# RockChip_RK3588 register map
Vendor: RockChip Electronics Co., Ltd.; Series: RK3588; File version: 0.1
Registers are 32-bit, read-write, no defined reset value unless marked. A register's access mark holds for its fields unless they carry their own. Offsets are from the block's base; [hi:lo] are bit positions; {n}, {i} and the like mark numbered series.

## IOC_BUS
Base 0xFD5F8000
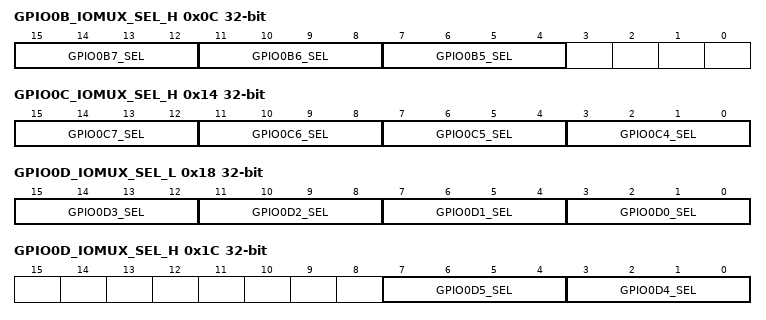
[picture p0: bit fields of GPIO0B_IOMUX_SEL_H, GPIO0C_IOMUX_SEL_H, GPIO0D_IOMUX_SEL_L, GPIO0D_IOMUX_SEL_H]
0x0C GPIO0B_IOMUX_SEL_H — GPIO0B IOMUX Select High bits
  [15:12] GPIO0B7_SEL
    8=SPI0_CS1_M0; 9=I2C2_SCL_M0; 11=CAN0_TX_M0; 12=PCIE30X1_1_PERSTN_M0
  [11:8] GPIO0B6_SEL
    9=I2C1_SDA_M0; 10=UART2_RX_M0; 12=PCIE30X1_1_WAKEN_M0
  [7:4] GPIO0B5_SEL
    9=I2C1_SCL_M0; 10=UART2_TX_M0; 12=PCIE30X1_1_CLKREQN_M0
0x10 GPIO0C_IOMUX_SEL_L — GPIO0C IOMUX Select Low bits
  [3:0] GPIO0C0_SEL
    8=SPI0_MOSI_M0; 9=I2C2_SDA_M0; 11=CAN0_RX_M0; 12=PCIE30X1_0_CLKREQN_M0
0x14 GPIO0C_IOMUX_SEL_H — GPIO0C IOMUX Select High bits
  [15:12] GPIO0C7_SEL
    8=SPI0_MISO_M0; 9=I2C6_SDA_M0; 10=UART1_RTSN_M2; 11=PWM6_M0; 12=PCIE30X4_WAKEN_M0
  [11:8] GPIO0C6_SEL
    8=SPI0_CLK_M0; 11=PWM5_M1; 12=PCIE30X4_CLKREQN_M0; 13=SATA_CP_POD
  [7:4] GPIO0C5_SEL
    9=I2C4_SCL_M2; 10=DP1_HPDIN_M1; 11=PWM4_M0; 12=PCIE30X1_0_PERSTN_M0
  [3:0] GPIO0C4_SEL
    9=I2C4_SDA_M2; 10=DP0_HPDIN_M1; 12=PCIE30X1_0_WAKEN_M0
0x18 GPIO0D_IOMUX_SEL_L — GPIO0D IOMUX Select Low bits
  [15:12] GPIO0D3_SEL
    8=SPI3_CLK_M2
  [11:8] GPIO0D2_SEL
    8=SPI3_MOSI_M2; 10=UART1_RX_M2; 11=HDMI_RX_SCL_M0; 12=PCIE30X2_WAKEN_M0; 13=HDMI_TX1_CEC_M1
  [7:4] GPIO0D1_SEL
    8=SPI0_CS0_M0; 10=UART1_TX_M2; 11=HDMI_RX_SDA_M0; 12=PCIE30X2_CLKREQN_M0; 13=HDMI_TX0_CEC_M1
  [3:0] GPIO0D0_SEL
    8=SPI3_MISO_M2; 9=I2C6_SCL_M0; 10=UART1_CTSN_M2; 11=PWM7_IR_M0; 12=PCIE30X4_PERSTN_M0
0x1C GPIO0D_IOMUX_SEL_H — GPIO0D IOMUX Select High bits
  [7:4] GPIO0D5_SEL
    8=SPI3_CS1_M2; 9=I2C1_SDA_M2; 10=CAN2_TX_M1; 11=HDMI_TX0_SCL_M1; 13=SATA_MP_SWITCH
  [3:0] GPIO0D4_SEL
    8=SPI3_CS0_M2; 9=I2C1_SCL_M2; 10=CAN2_RX_M1; 11=HDMI_TX0_SDA_M1; 12=PCIE30X2_PERSTN_M0; 13=SATA_CPDET
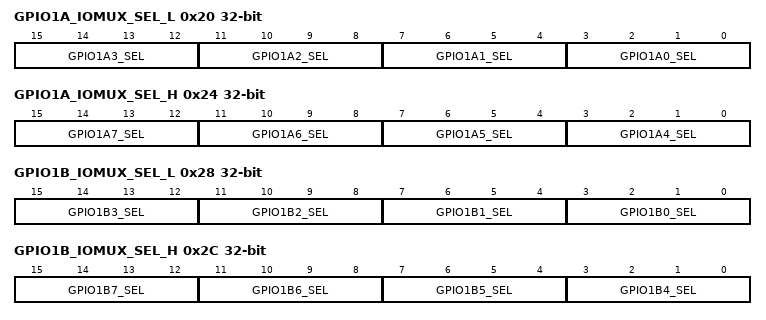
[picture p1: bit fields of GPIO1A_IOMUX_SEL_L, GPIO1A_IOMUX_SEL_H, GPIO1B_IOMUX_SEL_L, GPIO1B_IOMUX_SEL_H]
0x20 GPIO1A_IOMUX_SEL_L — GPIO1A IOMUX Select Low bits
  [15:12] GPIO1A3_SEL
    0=GPIO; 5=HDMI_TX1_SDA_M2; 8=SPI4_CS0_M2; 9=I2C4_SCL_M3; 10=UART6_CTSN_M1; 11=PWM1_M2
  [11:8] GPIO1A2_SEL
    0=GPIO; 1=VOP_POST_EMPTY; 8=SPI4_CLK_M2; 9=I2C4_SDA_M3; 10=UART6_RTSN_M1; 11=PWM0_M2
  [7:4] GPIO1A1_SEL
    0=GPIO; 4=PCIE30X1_1_WAKEN_M2; 5=DP1_HPDIN_M2; 6=SATA1_ACT_LED_M1; 8=SPI4_MOSI_M2; 9=I2C2_SCL_M4; 10=UART6_TX_M1
  [3:0] GPIO1A0_SEL
    0=GPIO; 4=PCIE30X1_1_CLKREQN_M2; 5=DP0_HPDIN_M2; 7=HDMI_DEBUG6; 8=SPI4_MISO_M2; 9=I2C2_SDA_M4; 10=UART6_RX_M1
0x24 GPIO1A_IOMUX_SEL_H — GPIO1A IOMUX Select High bits
  [15:12] GPIO1A7_SEL
    0=GPIO; 2=PDM1_SDI0_M1; 4=PCIE30X1_1_PERSTN_M2; 7=HDMI_DEBUG0; 8=SPI2_CS0_M0; 11=PWM3_IR_M3
  [11:8] GPIO1A6_SEL
    0=GPIO; 5=HDMI_TX1_HPD_M0; 8=SPI2_CLK_M0
  [7:4] GPIO1A5_SEL
    0=GPIO; 5=HDMI_TX0_HPD_M0; 8=SPI2_MOSI_M0
  [3:0] GPIO1A4_SEL
    0=GPIO; 5=HDMI_TX1_SCL_M2; 8=SPI2_MISO_M0
0x28 GPIO1B_IOMUX_SEL_L — GPIO1B IOMUX Select Low bits
  [15:12] GPIO1B3_SEL
    0=GPIO; 2=PDM1_CLK1_M1; 4=PCIE30X1_0_WAKEN_M2; 6=SATA0_ACT_LED_M1; 7=HDMI_DEBUG4; 8=SPI0_CLK_M2; 10=UART4_TX_M2
  [11:8] GPIO1B2_SEL
    0=GPIO; 2=PDM1_SDI3_M1; 4=PCIE30X4_PERSTN_M3; 7=HDMI_DEBUG3; 8=SPI0_MOSI_M2; 10=UART4_RX_M2
  [7:4] GPIO1B1_SEL
    0=GPIO; 2=PDM1_SDI2_M1; 4=PCIE30X4_WAKEN_M3; 7=HDMI_DEBUG2; 8=SPI0_MISO_M2
  [3:0] GPIO1B0_SEL
    0=GPIO; 2=PDM1_SDI1_M1; 4=PCIE30X4_CLKREQN_M3; 7=HDMI_DEBUG1; 8=SPI2_CS1_M0
0x2C GPIO1B_IOMUX_SEL_H — GPIO1B IOMUX Select High bits
  [15:12] GPIO1B7_SEL
    0=GPIO; 2=MIPI_CAMERA2_CLK_M0; 3=SPDIF1_TX_M0; 4=PCIE30X2_PERSTN_M3; 5=HDMI_RX_CEC_M2; 6=SATA2_ACT_LED_M1; 9=I2C5_SDA_M3; 10=UART1_RX_M1; 11=PWM13_M2
  [11:8] GPIO1B6_SEL
    0=GPIO; 2=MIPI_CAMERA1_CLK_M0; 3=SPDIF0_TX_M0; 4=PCIE30X2_WAKEN_M3; 5=HDMI_RX_HPDOUT_M2; 9=I2C5_SCL_M3; 10=UART1_TX_M1
  [7:4] GPIO1B5_SEL
    0=GPIO; 4=PCIE30X1_0_CLKREQN_M2; 8=SPI0_CS1_M2; 10=UART7_TX_M2
  [3:0] GPIO1B4_SEL
    0=GPIO; 2=PDM1_CLK0_M1; 4=PCIE30X1_0_PERSTN_M2; 7=HDMI_DEBUG5; 8=SPI0_CS0_M2; 10=UART7_RX_M2
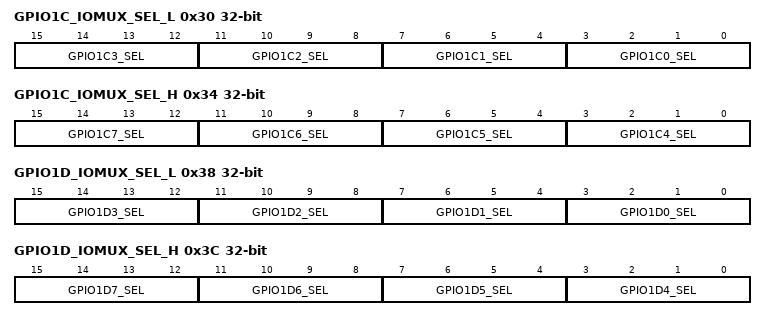
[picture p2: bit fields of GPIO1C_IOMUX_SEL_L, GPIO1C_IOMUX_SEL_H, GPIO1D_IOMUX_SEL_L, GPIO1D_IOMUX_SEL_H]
0x30 GPIO1C_IOMUX_SEL_L — GPIO1C IOMUX Select Low bits
  [15:12] GPIO1C3_SEL
    0=GPIO; 1=I2S0_SCLK; 8=SPI4_CS0_M0; 9=I2C6_SCL_M1; 10=UART3_CTSN; 11=PWM7_IR_M2
  [11:8] GPIO1C2_SEL
    0=GPIO; 1=I2S0_MCLK; 8=SPI4_CLK_M0; 9=I2C6_SDA_M1; 10=UART3_RTSN; 11=PWM3_IR_M2
  [7:4] GPIO1C1_SEL
    0=GPIO; 8=SPI4_MOSI_M0; 9=I2C3_SCL_M0; 10=UART3_TX_M0
  [3:0] GPIO1C0_SEL
    0=GPIO; 8=SPI4_MISO_M0; 9=I2C3_SDA_M0; 10=UART3_RX_M0
0x34 GPIO1C_IOMUX_SEL_H — GPIO1C IOMUX Select High bits
  [15:12] GPIO1C7_SEL
    0=GPIO; 1=I2S0_SDO0; 9=I2C4_SCL_M4; 10=UART4_CTSN
  [11:8] GPIO1C6_SEL
    0=GPIO; 3=PDM0_CLK0_M0; 9=I2C4_SDA_M4; 11=PWM15_IR_M2
  [7:4] GPIO1C5_SEL
    0=GPIO; 1=I2S0_LRCK; 9=I2C2_SCL_M3; 10=UART4_RTSN
  [3:0] GPIO1C4_SEL
    0=GPIO; 3=PDM0_CLK1_M0; 4=PCIE30PHY_DTB0; 8=SPI4_CS1_M0; 9=I2C2_SDA_M3; 11=PWM11_IR_M2
0x38 GPIO1D_IOMUX_SEL_L — GPIO1D IOMUX Select Low bits
  [15:12] GPIO1D3_SEL
    0=GPIO; 2=I2S0_SDI1; 3=PDM0_SDI3_M0; 8=SPI1_CS0_M2; 9=I2C1_SDA_M4; 10=UART4_RX_M0; 11=PWM1_M1
  [11:8] GPIO1D2_SEL
    0=GPIO; 1=I2S0_SDO3; 2=I2S0_SDI2; 3=PDM0_SDI2_M0; 8=SPI1_CLK_M2; 9=I2C1_SCL_M4; 10=UART4_TX_M0; 11=PWM0_M1
  [7:4] GPIO1D1_SEL
    0=GPIO; 1=I2S0_SDO2; 2=I2S0_SDI3; 3=PDM0_SDI1_M0; 4=PCIE30PHY_DTB1; 8=SPI1_MOSI_M2; 9=I2C7_SDA_M0; 10=UART6_RX_M2
  [3:0] GPIO1D0_SEL
    0=GPIO; 1=I2S0_SDO1; 8=SPI1_MISO_M2; 9=I2C7_SCL_M0; 10=UART6_TX_M2
0x3C GPIO1D_IOMUX_SEL_H — GPIO1D IOMUX Select High bits
  [15:12] GPIO1D7_SEL
    0=GPIO; 2=MIPI_CAMERA4_CLK_M0; 4=PCIE30X2_CLKREQN_M3; 5=HDMI_RX_SDA_M2; 9=I2C8_SDA_M2; 10=UART1_CTSN_M1; 11=PWM15_IR_M3
  [11:8] GPIO1D6_SEL
    0=GPIO; 2=MIPI_CAMERA3_CLK_M0; 5=HDMI_RX_SCL_M2; 9=I2C8_SCL_M2; 10=UART1_RTSN_M1; 11=PWM14_M2
  [7:4] GPIO1D5_SEL
    0=GPIO; 3=PDM0_SDI0_M0; 8=SPI1_CS1_M2
  [3:0] GPIO1D4_SEL
    0=GPIO; 2=I2S0_SDI0
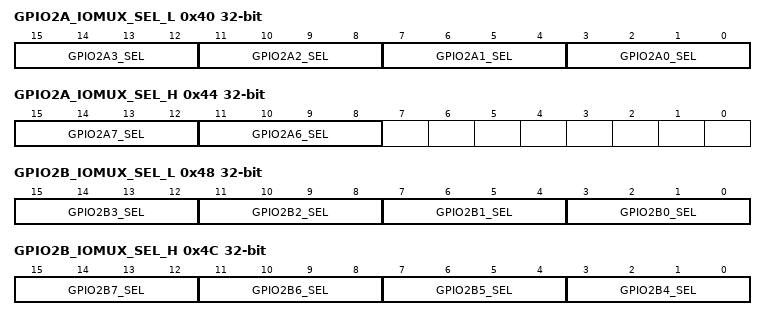
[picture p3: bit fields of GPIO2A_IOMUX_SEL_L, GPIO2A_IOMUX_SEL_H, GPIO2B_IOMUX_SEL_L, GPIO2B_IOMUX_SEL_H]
0x40 GPIO2A_IOMUX_SEL_L — GPIO2A IOMUX Select Low bits
  [15:12] GPIO2A3_SEL
    0=GPIO; 1=EMMC_RSTN; 9=I2C2_SCL_M2; 10=UART5_RTSN_M1
  [11:8] GPIO2A2_SEL
    0=GPIO; 1=EMMC_DATA_STROBE; 9=I2C2_SDA_M2; 10=UART5_CTSN_M1
  [7:4] GPIO2A1_SEL
    0=GPIO; 1=EMMC_CLKOUT
  [3:0] GPIO2A0_SEL
    0=GPIO; 1=EMMC_CMD; 2=FSPI_CLK_M0
0x44 GPIO2A_IOMUX_SEL_H — GPIO2A IOMUX Select High bits
  [15:12] GPIO2A7_SEL
    0=GPIO; 1=GMAC0_RXD3; 2=SDIO_D1_M0; 3=FSPI_D1_M1; 10=UART6_TX_M0
  [11:8] GPIO2A6_SEL
    0=GPIO; 1=GMAC0_RXD2; 2=SDIO_D0_M0; 3=FSPI_D0_M1; 10=UART6_RX_M0
0x48 GPIO2B_IOMUX_SEL_L — GPIO2B IOMUX Select Low bits
  [15:12] GPIO2B3_SEL
    0=GPIO; 1=GMAC0_TXCLK; 2=SDIO_CLK_M0; 3=FSPI_CLK_M1; 9=I2C3_SDA_M3
  [11:8] GPIO2B2_SEL
    0=GPIO; 1=GMAC0_TXD3; 2=SDIO_CMD_M0; 9=I2C3_SCL_M3
  [7:4] GPIO2B1_SEL
    0=GPIO; 1=GMAC0_TXD2; 2=SDIO_D3_M0; 3=FSPI_D3_M1; 9=I2C8_SDA_M1; 10=UART6_CTSN_M0
  [3:0] GPIO2B0_SEL
    0=GPIO; 1=GMAC0_RXCLK; 2=SDIO_D2_M0; 3=FSPI_D2_M1; 9=I2C8_SCL_M1; 10=UART6_RTSN_M0
0x4C GPIO2B_IOMUX_SEL_H — GPIO2B IOMUX Select High bits
  [15:12] GPIO2B7_SEL
    0=GPIO; 1=GMAC0_TXD1; 2=I2S2_SCLK_M0; 9=I2C5_SDA_M4; 10=UART1_TX_M0
  [11:8] GPIO2B6_SEL
    0=GPIO; 1=GMAC0_TXD0; 2=I2S2_MCLK_M0; 9=I2C5_SCL_M4; 10=UART1_RX_M0
  [7:4] GPIO2B5_SEL
    0=GPIO; 1=GMAC0_PPSTRING; 3=FSPI_CS1N_M1; 4=HDMI_TX1_SCL_M0; 9=I2C4_SCL_M1; 10=UART7_TX_M0
  [3:0] GPIO2B4_SEL
    0=GPIO; 1=GMAC0_PTP_REFCLK; 3=FSPI_CS0N_M1; 4=HDMI_TX1_SDA_M0; 9=I2C4_SDA_M1; 10=UART7_RX_M0
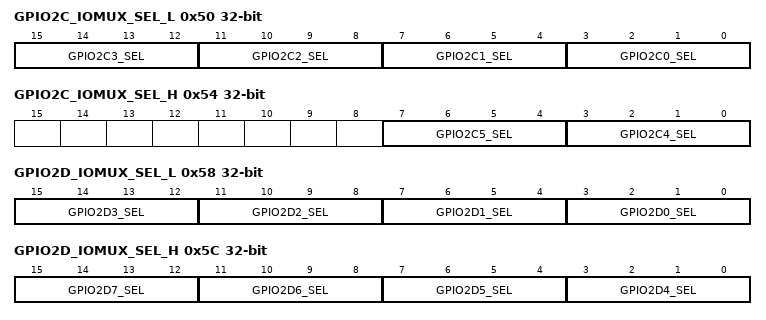
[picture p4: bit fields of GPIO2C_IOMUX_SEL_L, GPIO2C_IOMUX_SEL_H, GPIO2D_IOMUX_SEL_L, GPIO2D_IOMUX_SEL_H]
0x50 GPIO2C_IOMUX_SEL_L — GPIO2C IOMUX Select Low bits
  [15:12] GPIO2C3_SEL
    0=GPIO; 1=ETH0_REFCLKO_25M; 2=I2S2_SDI_M0; 8=SPI1_CS0_M0; 9=I2C6_SCL_M2
  [11:8] GPIO2C2_SEL
    0=GPIO; 1=GMAC0_RXD1; 8=SPI1_MOSI_M0; 9=I2C6_SDA_M2; 10=UART9_TX_M0
  [7:4] GPIO2C1_SEL
    0=GPIO; 1=GMAC0_RXD0; 8=SPI1_MISO_M0; 9=I2C2_SCL_M1; 10=UART1_CTSN_M0
  [3:0] GPIO2C0_SEL
    0=GPIO; 1=GMAC0_TXEN; 2=I2S2_LRCK_M0; 8=SPI1_CLK_M0; 9=I2C2_SDA_M1; 10=UART1_RTSN_M0
0x54 GPIO2C_IOMUX_SEL_H — GPIO2C IOMUX Select High bits
  [7:4] GPIO2C5_SEL
    0=GPIO; 1=CLK32K_OUT1
  [3:0] GPIO2C4_SEL
    0=GPIO; 1=GMAC0_PPSCLK; 3=TEST_CLKOUT_M1; 4=HDMI_TX1_CEC_M0; 8=SPI1_CS1_M0; 10=UART9_RX_M0
0x58 GPIO2D_IOMUX_SEL_L — GPIO2D IOMUX Select Low bits
  [4n+3:4n] GPIO2D{n}_SEL (n=0..3)
    0=GPIO; 1=EMMC_D{n}; 2=FSPI_D{n}_M0
0x5C GPIO2D_IOMUX_SEL_H — GPIO2D IOMUX Select High bits
  [15:12] GPIO2D7_SEL
    0=GPIO; 1=EMMC_D7; 2=FSPI_CS1N_M0
  [11:8] GPIO2D6_SEL
    0=GPIO; 1=EMMC_D6; 2=FSPI_CS0N_M0
  [7:4] GPIO2D5_SEL
    0=GPIO; 1=EMMC_D5; 9=I2C1_SDA_M3; 10=UART5_TX_M2
  [3:0] GPIO2D4_SEL
    0=GPIO; 1=EMMC_D4; 9=I2C1_SCL_M3; 10=UART5_RX_M2
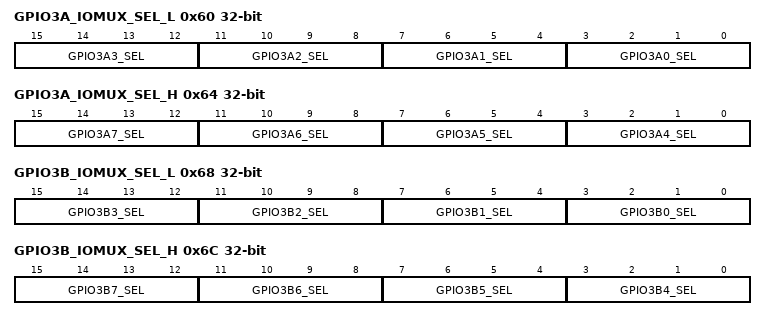
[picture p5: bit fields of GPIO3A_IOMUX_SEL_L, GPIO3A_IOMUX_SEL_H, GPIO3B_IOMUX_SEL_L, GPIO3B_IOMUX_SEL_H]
0x60 GPIO3A_IOMUX_SEL_L — GPIO3A IOMUX Select Low bits
  [15:12] GPIO3A3_SEL
    0=GPIO; 1=GMAC1_RXD3; 2=SDIO_D3_M1; 3=I2S3_SDO; 4=AUDDSM_RN; 5=FSPI_D3_M2; 8=SPI4_CS0_M1; 10=UART8_RX_M1
  [11:8] GPIO3A2_SEL
    0=GPIO; 1=GMAC1_RXD2; 2=SDIO_D2_M1; 3=I2S3_LRCK; 4=AUDDSM_LP; 5=FSPI_D2_M2; 8=SPI4_CLK_M1; 10=UART8_TX_M1
  [7:4] GPIO3A1_SEL
    0=GPIO; 1=GMAC1_TXD3; 2=SDIO_D1_M1; 3=I2S3_SCLK; 4=AUDDSM_LN; 5=FSPI_D1_M2; 8=SPI4_MOSI_M1; 9=I2C6_SCL_M4; 11=PWM11_IR_M0
  [3:0] GPIO3A0_SEL
    0=GPIO; 1=GMAC1_TXD2; 2=SDIO_D0_M1; 3=I2S3_MCLK; 5=FSPI_D0_M2; 8=SPI4_MISO_M1; 9=I2C6_SDA_M4; 11=PWM10_M0
0x64 GPIO3A_IOMUX_SEL_H — GPIO3A IOMUX Select High bits
  [15:12] GPIO3A7_SEL
    0=GPIO; 1=GMAC1_RXD0; 4=MIPI_CAMERA2_CLK_M1; 11=PWM8_M0
  [11:8] GPIO3A6_SEL
    0=GPIO; 1=ETH1_REFCLKO_25M; 4=MIPI_CAMERA1_CLK_M1; 9=I2C4_SCL_M0
  [7:4] GPIO3A5_SEL
    0=GPIO; 1=GMAC1_RXCLK; 2=SDIO_CLK_M1; 4=MIPI_CAMERA0_CLK_M1; 5=FSPI_CLK_M2; 9=I2C4_SDA_M0; 10=UART8_CTSN_M1
  [3:0] GPIO3A4_SEL
    0=GPIO; 1=GMAC1_TXCLK; 2=SDIO_CMD_M1; 3=I2S3_SDI; 4=AUDDSM_RP; 8=SPI4_CS1_M1; 10=UART8_RTSN_M1
0x68 GPIO3B_IOMUX_SEL_L — GPIO3B IOMUX Select Low bits
  [15:12] GPIO3B3_SEL
    0=GPIO; 1=GMAC1_TXD0; 3=I2S2_SDO_M1; 10=UART2_RTSN
  [11:8] GPIO3B2_SEL
    0=GPIO; 1=GMAC1_TXER; 3=I2S2_SDI_M1; 10=UART2_RX_M2; 11=PWM3_IR_M1
  [7:4] GPIO3B1_SEL
    0=GPIO; 1=GMAC1_RXDV_CRS; 4=MIPI_CAMERA4_CLK_M1; 10=UART2_TX_M2; 11=PWM2_M1
  [3:0] GPIO3B0_SEL
    0=GPIO; 1=GMAC1_RXD1; 4=MIPI_CAMERA3_CLK_M1; 11=PWM9_M0
0x6C GPIO3B_IOMUX_SEL_H — GPIO3B IOMUX Select High bits
  [15:12] GPIO3B7_SEL
    0=GPIO; 1=GMAC1_PTP_REF_CLK; 5=HDMI_TX1_HPD_M1; 8=SPI1_MOSI_M1; 9=I2C3_SCL_M1
  [11:8] GPIO3B6_SEL
    0=GPIO; 1=GMAC1_MCLKINOUT; 3=I2S2_LRCK_M1; 9=CAN1_TX_M0; 10=UART3_RX_M1; 11=PWM13_M0
  [7:4] GPIO3B5_SEL
    0=GPIO; 1=GMAC1_TXEN; 3=I2S2_SCLK_M1; 9=CAN1_RX_M0; 10=UART3_TX_M1; 11=PWM12_M0
  [3:0] GPIO3B4_SEL
    0=GPIO; 1=GMAC1_TXD1; 3=I2S2_MCLK_M1; 10=UART2_CTSN
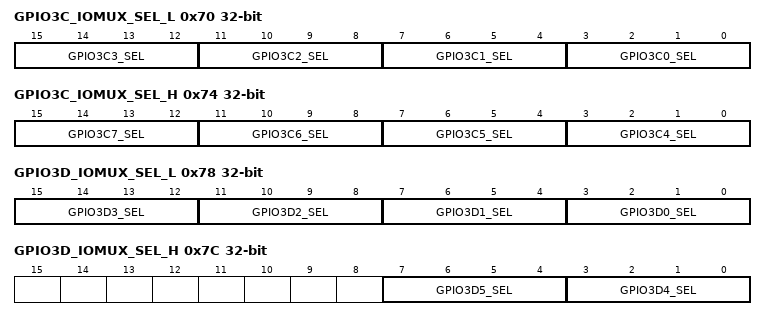
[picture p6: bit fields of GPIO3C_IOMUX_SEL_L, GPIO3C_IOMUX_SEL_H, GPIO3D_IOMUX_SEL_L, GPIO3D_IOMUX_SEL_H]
0x70 GPIO3C_IOMUX_SEL_L — GPIO3C IOMUX Select Low bits
  [15:12] GPIO3C3_SEL
    0=GPIO; 1=GMAC1_MDIO; 2=MIPI_TE1; 8=SPI1_CS1_M1; 9=I2C8_SDA_M4; 10=UART7_CTSN_M1; 11=PWM15_IR_M0
  [11:8] GPIO3C2_SEL
    0=GPIO; 1=GMAC1_MDC; 2=MIPI_TE0; 8=SPI1_CS0_M1; 9=I2C8_SCL_M4; 10=UART7_RTSN_M1; 11=PWM14_M0
  [7:4] GPIO3C1_SEL
    0=GPIO; 1=GMAC1_PPSCLK; 4=PCIE30X2_BUTTON_RSTN; 8=SPI1_CLK_M1; 10=UART7_RX_M1
  [3:0] GPIO3C0_SEL
    0=GPIO; 1=GMAC1_PPSTRIG; 8=SPI1_MISO_M1; 9=I2C3_SDA_M1; 10=UART7_TX_M1
0x74 GPIO3C_IOMUX_SEL_H — GPIO3C IOMUX Select High bits
  [15:12] GPIO3C7_SEL
    0=GPIO; 1=CIF_D11; 4=PCIE20X1_2_CLKREQN_M0; 5=HDMI_TX0_SCL_M2; 8=SPI3_MOSI_M3; 9=I2C5_SCL_M0
  [11:8] GPIO3C6_SEL
    0=GPIO; 1=CIF_D10; 4=PCIE30X4_PERSTN_M2; 5=HDMI_TX1_SCL_M1; 8=SPI3_MISO_M3
  [7:4] GPIO3C5_SEL
    0=GPIO; 1=CIF_D9; 2=FSPI_CS1N_M2; 4=PCIE30X4_WAKEN_M2; 5=HDMI_TX1_SDA_M1; 8=SPI3_CS1_M3; 9=CAN2_TX_M0; 10=UART5_RX_M1
  [3:0] GPIO3C4_SEL
    0=GPIO; 1=CIF_D8; 2=FSPI_CS0N_M2; 4=PCIE30X4_CLKREQN_M2; 5=HDMI_TX1_CEC_M2; 8=SPI3_CS0_M3; 9=CAN2_RX_M0; 10=UART5_TX_M1
0x78 GPIO3D_IOMUX_SEL_L — GPIO3D IOMUX Select Low bits
  [15:12] GPIO3D3_SEL
    0=GPIO; 1=CIF_D15; 4=PCIE30X2_WAKEN_M2; 5=HDMI_RX_SDA_M1; 8=SPI0_CLK_M3; 9=I2C7_SDA_M2; 10=UART9_CTSN_M2; 11=PWM10_M2
  [11:8] GPIO3D2_SEL
    0=GPIO; 1=CIF_D14; 4=PCIE30X2_CLKREQN_M2; 5=HDMI_RX_SCL_M1; 8=SPI0_MOSI_M3; 9=I2C7_SCL_M2; 10=UART9_RTSN_M2
  [7:4] GPIO3D1_SEL
    0=GPIO; 1=CIF_D13; 4=PCIE20X1_2_PERSTN_M0; 5=HDMI_RX_CEC_M1; 8=SPI0_MISO_M3; 10=UART4_TX_M1; 11=PWM9_M2
  [3:0] GPIO3D0_SEL
    0=GPIO; 1=CIF_D12; 4=PCIE20X1_2_WAKEN_M0; 5=HDMI_TX0_SDA_M2; 8=SPI3_CLK_M3; 9=I2C5_SDA_M0; 10=UART4_RX_M1; 11=PWM8_M2
0x7C GPIO3D_IOMUX_SEL_H — GPIO3D IOMUX Select High bits
  [7:4] GPIO3D5_SEL
    0=GPIO; 4=PCIE30X4_BUTTON_RSTN; 5=DP1_HPDIN_M0; 6=MCU_JTAG_TMS_M1; 8=SPI0_CS1_M3; 10=UART9_TX_M2; 11=PWM11_IR_M3
  [3:0] GPIO3D4_SEL
    0=GPIO; 3=HDMI_TX0_HPD_M1; 4=PCIE30X2_PERSTN_M2; 5=HDMI_RX_HPDOUT_M1; 6=MCU_JTAG_TCK_M1; 8=SPI0_CS0_M3; 10=UART9_RX_M2
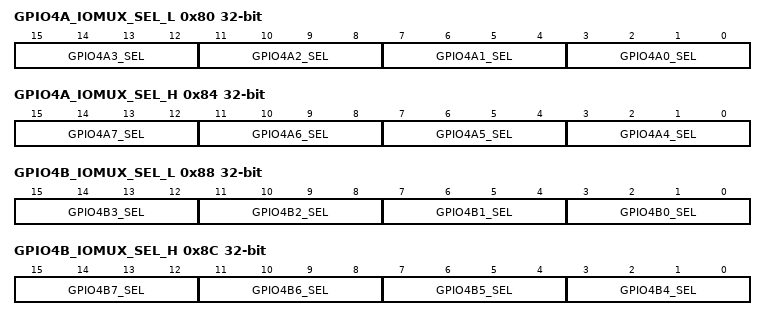
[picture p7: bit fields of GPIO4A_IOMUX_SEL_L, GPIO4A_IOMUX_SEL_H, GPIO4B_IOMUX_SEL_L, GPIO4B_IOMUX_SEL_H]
0x80 GPIO4A_IOMUX_SEL_L — GPIO4A IOMUX Select Low bits
  [15:12] GPIO4A3_SEL
    0=GPIO; 1=CIF_D3; 2=BT1120_D3; 4=PCIE30X1_0_CLKREQN_M1; 7=DDRPHYCH0_DTB3; 10=UART0_TX_M2
  [11:8] GPIO4A2_SEL
    0=GPIO; 1=CIF_D2; 2=BT1120_D2; 3=I2S1_LRCK_M0; 4=PCIE30X1_1_PERSTN_M1; 7=DDRPHYCH0_DTB2; 8=SPI0_CLK_M1
  [7:4] GPIO4A1_SEL
    0=GPIO; 1=CIF_D1; 2=BT1120_D1; 3=I2S1_SCLK_M0; 4=PCIE30X1_1_WAKEN_M1; 7=DDRPHYCH0_DTB1; 8=SPI0_MOSI_M1; 10=UART9_CTSN_M1
  [3:0] GPIO4A0_SEL
    0=GPIO; 1=CIF_D0; 2=BT1120_D0; 3=I2S1_MCLK_M0; 4=PCIE30X1_1_CLKREQN_M1; 7=DDRPHYCH0_DTB0; 8=SPI0_MISO_M1; 10=UART9_RTSN_M1
0x84 GPIO4A_IOMUX_SEL_H — GPIO4A IOMUX Select High bits
  [15:12] GPIO4A7_SEL
    0=GPIO; 1=CIF_D7; 2=BT1120_D7; 3=I2S1_SDI2_M0; 4=PCIE30X2_WAKEN_M1; 7=DDRPHYCH1_DTB3; 8=SPI2_CS0_M1; 9=I2C5_SDA_M2
  [11:8] GPIO4A6_SEL
    0=GPIO; 1=CIF_D6; 2=BT1120_D6; 3=I2S1_SDI1_M0; 4=PCIE30X2_CLKREQN_M1; 7=DDRPHYCH1_DTB2; 8=SPI2_CLK_M1; 9=I2C5_SCL_M2; 10=UART3_RX_M2
  [7:4] GPIO4A5_SEL
    0=GPIO; 1=CIF_D5; 2=BT1120_D5; 3=I2S1_SDI0_M0; 4=PCIE30X1_0_PERSTN_M1; 7=DDRPHYCH1_DTB1; 8=SPI2_MOSI_M1; 9=I2C3_SDA_M2; 10=UART3_TX_M2
  [3:0] GPIO4A4_SEL
    0=GPIO; 1=CIF_D4; 2=BT1120_D4; 4=PCIE30X1_0_WAKEN_M1; 7=DDRPHYCH1_DTB0; 8=SPI2_MISO_M1; 9=I2C3_SCL_M2; 10=UART0_RX_M2
0x88 GPIO4B_IOMUX_SEL_L — GPIO4B IOMUX Select Low bits
  [15:12] GPIO4B3_SEL
    0=GPIO; 1=CIF_VSYNC; 2=BT1120_D9; 3=I2S1_SDO2_M0; 4=PCIE20X1_2_BUTTON_RSTN; 7=DDRPHYCH2_DTB3; 9=I2C7_SDA_M3; 10=UART8_CTSN_M0; 11=PWM15_IR_M1; 12=CAN1_TX_M1
  [11:8] GPIO4B2_SEL
    0=GPIO; 1=CIF_HREF; 2=BT1120_D8; 3=I2S1_SDO1_M0; 4=PCIE30X1_1_BUTTON_RSTN; 7=DDRPHYCH2_DTB2; 8=SPI0_CS0_M1; 9=I2C7_SCL_M3; 10=UART8_RTSN_M0; 11=PWM14_M1; 12=CAN1_RX_M1
  [7:4] GPIO4B1_SEL
    0=GPIO; 1=MIPI_CAMERA0_CLK_M0; 2=SPDIF1_TX_M1; 3=I2S1_SDO0_M0; 4=PCIE30X1_0_BUTTON_RSTN; 6=SATA2_ACT_LED_M0; 7=DDRPHYCH2_DTB1; 8=SPI0_CS1_M1; 9=I2C6_SCL_M3; 10=UART8_RX_M0
  [3:0] GPIO4B0_SEL
    0=GPIO; 1=CIF_CLKIN; 2=BT1120_CLKOUT; 3=I2S1_SDI3_M0; 4=PCIE30X2_PERSTN_M1; 7=DDRPHYCH2_DTB0; 8=SPI2_CS1_M1; 9=I2C6_SDA_M3; 10=UART8_TX_M0
0x8C GPIO4B_IOMUX_SEL_H — GPIO4B IOMUX Select High bits
  [15:12] GPIO4B7_SEL
    0=GPIO; 2=BT1120_D13; 4=PCIE20X1_2_CLKREQN_M1; 5=HDMI_TX0_SCL_M0; 7=DDRPHYCH3_DTB3; 8=SPI3_CLK_M1; 9=I2C5_SDA_M1
  [11:8] GPIO4B6_SEL
    0=GPIO; 2=BT1120_D12; 4=PCIE30X4_PERSTN_M1; 5=HDMI_RX_HPDOUT_M0; 6=SATA0_ACT_LED_M0; 7=DDRPHYCH3_DTB2; 8=SPI3_MOSI_M1; 9=I2C5_SCL_M1; 11=PWM13_M1
  [7:4] GPIO4B5_SEL
    0=GPIO; 2=BT1120_D11; 4=PCIE30X4_WAKEN_M1; 5=HDMI_RX_CEC_M0; 6=SATA1_ACT_LED_M0; 7=DDRPHYCH3_DTB1; 8=SPI3_MISO_M1; 10=UART9_RX_M1; 11=PWM12_M1
  [3:0] GPIO4B4_SEL
    0=GPIO; 1=CIF_CLKOUT; 2=BT1120_D10; 3=I2S1_SDO3_M0; 4=PCIE30X4_CLKREQN_M1; 5=DP0_HPDIN_M0; 6=SPDIF0_TX_M1; 7=DDRPHYCH3_DTB0; 10=UART9_TX_M1; 11=PWM11_IR_M1
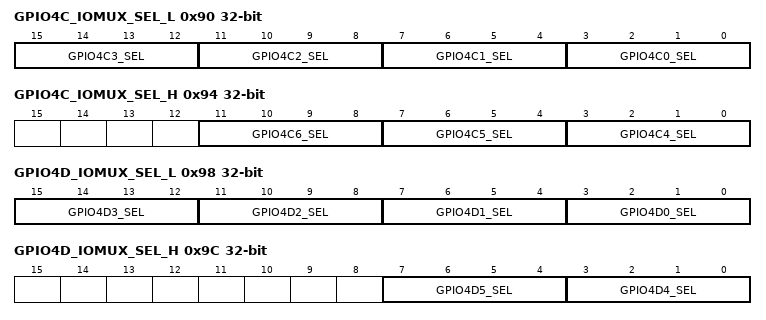
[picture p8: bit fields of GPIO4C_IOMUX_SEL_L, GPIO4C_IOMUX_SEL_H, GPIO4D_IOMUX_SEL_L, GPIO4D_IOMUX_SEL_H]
0x90 GPIO4C_IOMUX_SEL_L — GPIO4C IOMUX Select Low bits
  [15:12] GPIO4C3_SEL
    0=GPIO; 1=GMAC0_MCLKINOUT; 2=I2S2_SDO_M0; 8=SPI3_CS1_M0; 9=I2C7_SCL_M1; 11=PWM4_M1
  [11:8] GPIO4C2_SEL
    0=GPIO; 1=GMAC0_RXDV_CRS; 8=SPI3_CS0_M0; 10=UART7_RTSN_M0; 11=PWM2_M2
  [7:4] GPIO4C1_SEL
    0=GPIO; 2=BT1120_D15; 3=SPDIF1_TX_M2; 4=PCIE20X1_2_PERSTN_M1; 5=HDMI_TX0_CEC_M0; 8=SPI3_CS1_M1; 9=I2C8_SDA_M3; 11=PWM6_M1
  [3:0] GPIO4C0_SEL
    0=GPIO; 2=BT1120_D14; 4=PCIE20X1_2_WAKEN_M1; 5=HDMI_TX0_SDA_M0; 8=SPI3_CS0_M1; 9=I2C8_SCL_M3
0x94 GPIO4C_IOMUX_SEL_H — GPIO4C IOMUX Select High bits
  [11:8] GPIO4C6_SEL
    0=GPIO; 1=GMAC0_TXER; 8=SPI3_CLK_M0; 9=I2C0_SDA_M1; 10=UART7_CTSN_M0; 11=PWM7_IR_M3
  [7:4] GPIO4C5_SEL
    0=GPIO; 1=GMAC0_MDIO; 8=SPI3_MOSI_M0; 9=I2C0_SCL_M1; 10=UART9_CTSN_M0; 11=PWM6_M2
  [3:0] GPIO4C4_SEL
    0=GPIO; 1=GMAC0_MDC; 8=SPI3_MISO_M0; 9=I2C7_SDA_M1; 10=UART9_RTSN_M0; 11=PWM5_M2
0x98 GPIO4D_IOMUX_SEL_L — GPIO4D IOMUX Select Low bits
  [15:12] GPIO4D3_SEL
    0=GPIO; 1=SDMMC_D3; 2=PDM1_SDI0_M0; 5=JTAG_TMS_M0; 9=I2C8_SDA_M0; 10=UART5_RTSN_M0; 11=PWM10_M1
  [11:8] GPIO4D2_SEL
    0=GPIO; 1=SDMMC_D2; 2=PDM1_SDI1_M0; 5=JTAG_TCK_M0; 9=I2C8_SCL_M0; 10=UART5_CTSN_M0
  [7:4] GPIO4D1_SEL
    0=GPIO; 1=SDMMC_D1; 2=PDM1_SDI2_M0; 5=JTAG_TMS_M1; 9=I2C3_SDA_M4; 10=UART2_RX_M1; 11=PWM9_M1
  [3:0] GPIO4D0_SEL
    0=GPIO; 1=SDMMC_D0; 2=PDM1_SDI3_M0; 5=JTAG_TCK_M1; 9=I2C3_SCL_M4; 10=UART2_TX_M1; 11=PWM8_M1
0x9C GPIO4D_IOMUX_SEL_H — GPIO4D IOMUX Select High bits
  [7:4] GPIO4D5_SEL
    0=GPIO; 1=SDMMC_CLK; 2=PDM1_CLK0_M0; 4=TEST_CLKOUT_M0; 5=MCU_JTAG_TMS_M0; 9=CAN0_RX_M1; 10=UART5_TX_M0
  [3:0] GPIO4D4_SEL
    0=GPIO; 1=SDMMC_CMD; 2=PDM1_CLK1_M0; 5=MCU_JTAG_TCK_M0; 9=CAN0_TX_M1; 10=UART5_RX_M0; 11=PWM7_IR_M1
